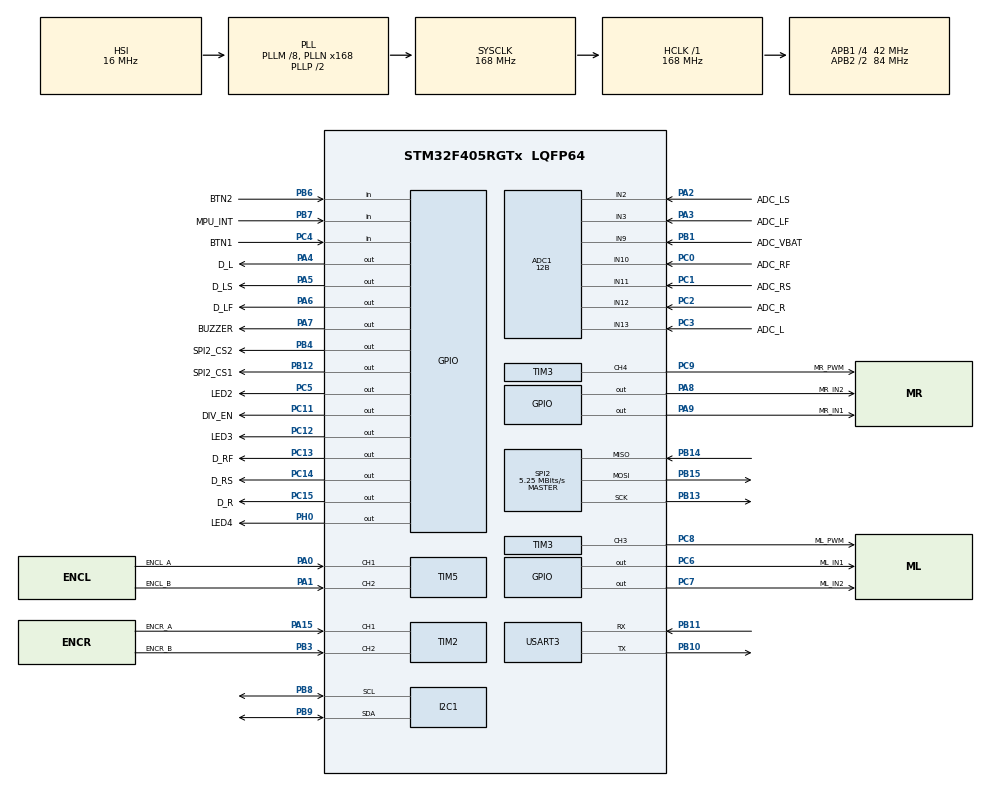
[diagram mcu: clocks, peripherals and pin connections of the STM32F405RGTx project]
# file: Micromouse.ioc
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ADC1.Channel-15\#ChannelRegularConversion=ADC_CHANNEL_12
ADC1.Channel-16\#ChannelRegularConversion=ADC_CHANNEL_2
ADC1.Channel-17\#ChannelRegularConversion=ADC_CHANNEL_11
ADC1.Channel-18\#ChannelRegularConversion=ADC_CHANNEL_3
ADC1.Channel-19\#ChannelRegularConversion=ADC_CHANNEL_10
ADC1.Channel-8\#ChannelRegularConversion=ADC_CHANNEL_13
ADC1.ClockPrescaler=ADC_CLOCK_SYNC_PCLK_DIV4
ADC1.ContinuousConvMode=DISABLE
ADC1.DMAContinuousRequests=ENABLE
ADC1.DataAlign=ADC_DATAALIGN_RIGHT
ADC1.DiscontinuousConvMode=DISABLE
ADC1.EOCSelection=ADC_EOC_SEQ_CONV
ADC1.EnableAnalogWatchDog=false
ADC1.ExternalTrigConv=ADC_SOFTWARE_START
ADC1.ExternalTrigConvEdge=ADC_EXTERNALTRIGCONVEDGE_NONE
ADC1.InjNumberOfConversion=0
ADC1.NbrOfConversion=6
ADC1.NbrOfConversionFlag=1
ADC1.Rank-15\#ChannelRegularConversion=2
ADC1.Rank-16\#ChannelRegularConversion=3
ADC1.Rank-17\#ChannelRegularConversion=4
ADC1.Rank-18\#ChannelRegularConversion=5
ADC1.Rank-19\#ChannelRegularConversion=6
ADC1.Rank-8\#ChannelRegularConversion=1
ADC1.Resolution=ADC_RESOLUTION_12B
ADC1.SamplingTime-15\#ChannelRegularConversion=ADC_SAMPLETIME_84CYCLES
ADC1.SamplingTime-16\#ChannelRegularConversion=ADC_SAMPLETIME_84CYCLES
ADC1.SamplingTime-17\#ChannelRegularConversion=ADC_SAMPLETIME_84CYCLES
ADC1.SamplingTime-18\#ChannelRegularConversion=ADC_SAMPLETIME_84CYCLES
ADC1.SamplingTime-19\#ChannelRegularConversion=ADC_SAMPLETIME_84CYCLES
ADC1.SamplingTime-8\#ChannelRegularConversion=ADC_SAMPLETIME_84CYCLES
ADC1.ScanConvMode=ENABLE
ADC1.master=1
Dma.ADC1.3.Direction=DMA_PERIPH_TO_MEMORY
Dma.ADC1.3.FIFOMode=DMA_FIFOMODE_DISABLE
Dma.ADC1.3.Instance=DMA2_Stream0
Dma.ADC1.3.MemDataAlignment=DMA_MDATAALIGN_WORD
Dma.ADC1.3.MemInc=DMA_MINC_ENABLE
Dma.ADC1.3.Mode=DMA_NORMAL
Dma.ADC1.3.PeriphDataAlignment=DMA_PDATAALIGN_WORD
Dma.ADC1.3.PeriphInc=DMA_PINC_DISABLE
Dma.ADC1.3.Priority=DMA_PRIORITY_HIGH
Dma.I2C1_RX.0.Direction=DMA_PERIPH_TO_MEMORY
Dma.I2C1_RX.0.FIFOMode=DMA_FIFOMODE_DISABLE
Dma.I2C1_RX.0.Instance=DMA1_Stream0
Dma.I2C1_RX.0.MemDataAlignment=DMA_MDATAALIGN_BYTE
Dma.I2C1_RX.0.MemInc=DMA_MINC_ENABLE
Dma.I2C1_RX.0.Mode=DMA_NORMAL
Dma.I2C1_RX.0.PeriphDataAlignment=DMA_PDATAALIGN_BYTE
Dma.I2C1_RX.0.PeriphInc=DMA_PINC_DISABLE
Dma.I2C1_RX.0.Priority=DMA_PRIORITY_HIGH
Dma.Request0=I2C1_RX
Dma.Request1=USART3_TX
Dma.Request2=USART3_RX
Dma.Request3=ADC1
Dma.USART3_RX.2.Direction=DMA_PERIPH_TO_MEMORY
Dma.USART3_RX.2.FIFOMode=DMA_FIFOMODE_DISABLE
Dma.USART3_RX.2.Instance=DMA1_Stream1
Dma.USART3_RX.2.MemDataAlignment=DMA_MDATAALIGN_BYTE
Dma.USART3_RX.2.MemInc=DMA_MINC_ENABLE
Dma.USART3_RX.2.Mode=DMA_NORMAL
Dma.USART3_RX.2.PeriphDataAlignment=DMA_PDATAALIGN_BYTE
Dma.USART3_RX.2.PeriphInc=DMA_PINC_DISABLE
Dma.USART3_RX.2.Priority=DMA_PRIORITY_LOW
Dma.USART3_TX.1.Direction=DMA_MEMORY_TO_PERIPH
Dma.USART3_TX.1.FIFOMode=DMA_FIFOMODE_DISABLE
Dma.USART3_TX.1.Instance=DMA1_Stream3
Dma.USART3_TX.1.MemDataAlignment=DMA_MDATAALIGN_BYTE
Dma.USART3_TX.1.MemInc=DMA_MINC_ENABLE
Dma.USART3_TX.1.Mode=DMA_NORMAL
Dma.USART3_TX.1.PeriphDataAlignment=DMA_PDATAALIGN_BYTE
Dma.USART3_TX.1.PeriphInc=DMA_PINC_DISABLE
Dma.USART3_TX.1.Priority=DMA_PRIORITY_LOW
Mcu.Family=STM32F4
Mcu.Name=STM32F405RGTx
Mcu.Package=LQFP64
NVIC.DMA1_Stream0_IRQn=true\:0\:0\:false\:false\:true\:false
NVIC.DMA1_Stream1_IRQn=true\:0\:0\:false\:false\:true\:false
NVIC.DMA1_Stream3_IRQn=true\:0\:0\:false\:false\:true\:false
NVIC.DMA2_Stream0_IRQn=true\:0\:0\:false\:false\:true\:true
NVIC.I2C1_EV_IRQn=true\:0\:0\:false\:false\:true\:true
NVIC.PriorityGroup=NVIC_PRIORITYGROUP_4
NVIC.TIM1_UP_TIM10_IRQn=true\:0\:0\:false\:false\:true\:true
NVIC.TIM7_IRQn=true\:0\:0\:false\:false\:true\:true
PA0-WKUP.GPIO_Label=ENCL_A
PA0-WKUP.Signal=S_TIM5_CH1
PA1.GPIO_Label=ENCL_B
PA1.Signal=S_TIM5_CH2
PA13.Mode=Serial_Wire
PA13.Signal=SYS_JTMS-SWDIO
PA14.Mode=Serial_Wire
PA14.Signal=SYS_JTCK-SWCLK
PA15.GPIO_Label=ENCR_A
PA15.Signal=S_TIM2_CH1_ETR
PA2.GPIO_Label=ADC_LS
PA2.Signal=ADCx_IN2
PA3.GPIO_Label=ADC_LF
PA3.Signal=ADCx_IN3
PA4.GPIO_Label=D_L
PA4.GPIO_PuPd=GPIO_PULLDOWN
PA4.Signal=GPIO_Output
PA5.GPIO_Label=D_LS
PA5.GPIO_PuPd=GPIO_PULLDOWN
PA5.Signal=GPIO_Output
PA6.GPIO_Label=D_LF
PA6.GPIO_PuPd=GPIO_PULLDOWN
PA6.Signal=GPIO_Output
PA7.GPIO_Label=BUZZER
PA7.GPIO_PuPd=GPIO_PULLDOWN
PA7.Signal=GPIO_Output
PA8.GPIO_Label=MR_IN2
PA8.Signal=GPIO_Output
PA9.GPIO_Label=MR_IN1
PA9.Signal=GPIO_Output
PB1.GPIO_Label=ADC_VBAT
PB1.Signal=ADCx_IN9
PB10.Mode=Asynchronous
PB10.Signal=USART3_TX
PB11.Mode=Asynchronous
PB11.Signal=USART3_RX
PB12.GPIO_Label=SPI2_CS1
PB12.GPIO_PuPd=GPIO_PULLUP
PB12.PinState=GPIO_PIN_SET
PB12.Signal=GPIO_Output
PB13.Mode=Full_Duplex_Master
PB13.Signal=SPI2_SCK
PB14.Mode=Full_Duplex_Master
PB14.Signal=SPI2_MISO
PB15.Mode=Full_Duplex_Master
PB15.Signal=SPI2_MOSI
PB3.GPIO_Label=ENCR_B
PB3.Signal=S_TIM2_CH2
PB4.GPIO_Label=SPI2_CS2
PB4.GPIO_PuPd=GPIO_PULLUP
PB4.PinState=GPIO_PIN_SET
PB4.Signal=GPIO_Output
PB6.GPIO_Label=BTN2
PB6.Signal=GPIO_Input
PB7.GPIO_Label=MPU_INT
PB7.Signal=GPIO_Input
PB8.Mode=I2C
PB8.Signal=I2C1_SCL
PB9.Mode=I2C
PB9.Signal=I2C1_SDA
PC0.GPIO_Label=ADC_RF
PC0.Signal=ADCx_IN10
PC1.GPIO_Label=ADC_RS
PC1.Signal=ADCx_IN11
PC11.GPIO_Label=DIV_EN
PC11.GPIO_PuPd=GPIO_PULLDOWN
PC11.Signal=GPIO_Output
PC12.GPIO_Label=LED3
PC12.PinState=GPIO_PIN_SET
PC12.Signal=GPIO_Output
PC13-ANTI_TAMP.GPIO_Label=D_RF
PC13-ANTI_TAMP.GPIO_PuPd=GPIO_PULLDOWN
PC13-ANTI_TAMP.Signal=GPIO_Output
PC14-OSC32_IN.GPIO_Label=D_RS
PC14-OSC32_IN.GPIO_PuPd=GPIO_PULLDOWN
PC14-OSC32_IN.Signal=GPIO_Output
PC15-OSC32_OUT.GPIO_Label=D_R
PC15-OSC32_OUT.GPIO_PuPd=GPIO_PULLDOWN
PC15-OSC32_OUT.Signal=GPIO_Output
PC2.GPIO_Label=ADC_R
PC2.Signal=ADCx_IN12
PC3.GPIO_Label=ADC_L
PC3.Signal=ADCx_IN13
PC4.GPIO_Label=BTN1
PC4.Signal=GPIO_Input
PC5.GPIO_Label=LED2
PC5.PinState=GPIO_PIN_SET
PC5.Signal=GPIO_Output
PC6.GPIO_Label=ML_IN1
PC6.Signal=GPIO_Output
PC7.GPIO_Label=ML_IN2
PC7.Signal=GPIO_Output
PC8.GPIO_Label=ML_PWM
PC8.Signal=S_TIM3_CH3
PC9.GPIO_Label=MR_PWM
PC9.Signal=S_TIM3_CH4
PH0-OSC_IN.GPIO_Label=LED4
PH0-OSC_IN.PinState=GPIO_PIN_SET
PH0-OSC_IN.Signal=GPIO_Output
ProjectManager.HeapSize=0x200
ProjectManager.StackSize=0x400
ProjectManager.TargetToolchain=SW4STM32
RCC.48MHZClocksFreq_Value=84000000
RCC.AHBFreq_Value=168000000
RCC.APB1CLKDivider=RCC_HCLK_DIV4
RCC.APB1Freq_Value=42000000
RCC.APB1TimFreq_Value=84000000
RCC.APB2CLKDivider=RCC_HCLK_DIV2
RCC.APB2Freq_Value=84000000
RCC.APB2TimFreq_Value=168000000
RCC.CortexFreq_Value=168000000
RCC.HCLKFreq_Value=168000000
RCC.HSE_VALUE=8000000
RCC.HSI_VALUE=16000000
RCC.LSE_VALUE=32768
RCC.PLLM=8
RCC.PLLN=168
RCC.SYSCLKFreq_VALUE=168000000
RCC.SYSCLKSource=RCC_SYSCLKSOURCE_PLLCLK
RCC.VCOOutputFreq_Value=336000000
SH.ADCx_IN10.0=ADC1_IN10,IN10
SH.ADCx_IN11.0=ADC1_IN11,IN11
SH.ADCx_IN12.0=ADC1_IN12,IN12
SH.ADCx_IN13.0=ADC1_IN13,IN13
SH.ADCx_IN2.0=ADC1_IN2,IN2
SH.ADCx_IN3.0=ADC1_IN3,IN3
SH.ADCx_IN9.0=ADC1_IN9,IN9
SH.S_TIM2_CH1_ETR.0=TIM2_CH1,Encoder_Interface
SH.S_TIM2_CH2.0=TIM2_CH2,Encoder_Interface
SH.S_TIM3_CH3.0=TIM3_CH3,PWM Generation3 CH3
SH.S_TIM3_CH4.0=TIM3_CH4,PWM Generation4 CH4
SH.S_TIM5_CH1.0=TIM5_CH1,Encoder_Interface
SH.S_TIM5_CH2.0=TIM5_CH2,Encoder_Interface
SPI2.BaudRatePrescaler=SPI_BAUDRATEPRESCALER_8
SPI2.CLKPhase=SPI_PHASE_2EDGE
SPI2.CalculateBaudRate=5.25 MBits/s
SPI2.DataSize=SPI_DATASIZE_16BIT
SPI2.Direction=SPI_DIRECTION_2LINES
SPI2.Mode=SPI_MODE_MASTER
SPI2.VirtualType=VM_MASTER
TIM10.Period=1000
TIM10.Prescaler=65535
TIM3.Channel-PWM\ Generation3\ CH3=TIM_CHANNEL_3
TIM3.Channel-PWM\ Generation4\ CH4=TIM_CHANNEL_4
TIM7.Period=39
TIM7.Prescaler=84
USART3.VirtualMode=VM_ASYNC
VP_ADC1_TempSens_Input.Mode=IN-TempSens
VP_ADC1_Vref_Input.Mode=IN-Vrefint
VP_TIM10_VS_ClockSourceINT.Mode=Enable_Timer
VP_TIM6_VS_ClockSourceINT.Mode=Enable_Timer
VP_TIM7_VS_ClockSourceINT.Mode=Enable_Timer
board=Micromouse

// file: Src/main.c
/**
  ******************************************************************************
  * File Name          : main.c
  * Description        : Main program body
  ******************************************************************************
  ** This notice applies to any and all portions of this file
  * that are not between comment pairs USER CODE BEGIN and
  * USER CODE END. Other portions of this file, whether
  * inserted by the user or by software development tools
  * are owned by their respective copyright owners.
  *
  * COPYRIGHT(c) 2017 STMicroelectronics
  *
  * Redistribution and use in source and binary forms, with or without modification,
  * are permitted provided that the following conditions are met:
  *   1. Redistributions of source code must retain the above copyright notice,
  *      this list of conditions and the following disclaimer.
  *   2. Redistributions in binary form must reproduce the above copyright notice,
  *      this list of conditions and the following disclaimer in the documentation
  *      and/or other materials provided with the distribution.
  *   3. Neither the name of STMicroelectronics nor the names of its contributors
  *      may be used to endorse or promote products derived from this software
  *      without specific prior written permission.
  *
  * THIS SOFTWARE IS PROVIDED BY THE COPYRIGHT HOLDERS AND CONTRIBUTORS "AS IS"
  * AND ANY EXPRESS OR IMPLIED WARRANTIES, INCLUDING, BUT NOT LIMITED TO, THE
  * IMPLIED WARRANTIES OF MERCHANTABILITY AND FITNESS FOR A PARTICULAR PURPOSE ARE
  * DISCLAIMED. IN NO EVENT SHALL THE COPYRIGHT HOLDER OR CONTRIBUTORS BE LIABLE
  * FOR ANY DIRECT, INDIRECT, INCIDENTAL, SPECIAL, EXEMPLARY, OR CONSEQUENTIAL
  * DAMAGES (INCLUDING, BUT NOT LIMITED TO, PROCUREMENT OF SUBSTITUTE GOODS OR
  * SERVICES; LOSS OF USE, DATA, OR PROFITS; OR BUSINESS INTERRUPTION) HOWEVER
  * CAUSED AND ON ANY THEORY OF LIABILITY, WHETHER IN CONTRACT, STRICT LIABILITY,
  * OR TORT (INCLUDING NEGLIGENCE OR OTHERWISE) ARISING IN ANY WAY OUT OF THE USE
  * OF THIS SOFTWARE, EVEN IF ADVISED OF THE POSSIBILITY OF SUCH DAMAGE.
  *
  ******************************************************************************
  */
#include "main.h"
#include "stm32f4xx_hal.h"
#include "adc.h"
#include "dma.h"
#include "i2c.h"
#include "spi.h"
#include "tim.h"
#include "usart.h"
#include "gpio.h"

/* USER CODE BEGIN Includes */
//#include "port/as5147p.h"
//#include "port/mpu6050.h"
//#include "utils/logger.h"
//#include "Utils/fusion.h"
#include "mymain.h"

/* USER CODE END Includes */

/* USER CODE BEGIN PV */
/* Private variables ---------------------------------------------------------*/

/* USER CODE END PV */

void SystemClock_Config(void);

/* USER CODE BEGIN PFP */
/* Private function prototypes -----------------------------------------------*/

/* USER CODE END PFP */

/* USER CODE BEGIN 0 */
int16_t test[6];
/* USER CODE END 0 */

int main(void)
{

  /* MCU Configuration----------------------------------------------------------*/

  /* Reset of all peripherals, Initializes the Flash interface and the Systick. */
  HAL_Init();

  /* Configure the system clock */
  SystemClock_Config();

  /* Initialize all configured peripherals */
  MX_GPIO_Init();
  MX_DMA_Init();
  MX_ADC1_Init();
  MX_TIM6_Init();
  MX_TIM2_Init();
  MX_TIM5_Init();
  MX_I2C1_Init();
  MX_SPI2_Init();
  MX_TIM3_Init();
  MX_USART3_UART_Init();
  MX_TIM7_Init();
  MX_TIM10_Init();

  /* USER CODE BEGIN 2 */
  //HAL_TIM_Base_Start_IT(&htim7); // led timer
	//logger_init();
//	if(mpu_self_test()){
//		while(1);
//	}
//	mpu_init();
//	mpu_calibrate();
//  if(mpu_selftest())
//	  while(1);
  /* USER CODE BEGIN 2 */

	initModules();
  /* USER CODE END 2 */

  /* Infinite loop */
  while (1)
  {

  /* USER CODE BEGIN 3 */
	everyCycleFun();
  	HAL_Delay(1);
//  	everyCycleFun();

  }
  /* USER CODE END 3 */

}

/** System Clock Configuration
*/
void SystemClock_Config(void)
{

  RCC_OscInitTypeDef RCC_OscInitStruct;
  RCC_ClkInitTypeDef RCC_ClkInitStruct;

    /**Configure the main internal regulator output voltage
    */
  __HAL_RCC_PWR_CLK_ENABLE();

  __HAL_PWR_VOLTAGESCALING_CONFIG(PWR_REGULATOR_VOLTAGE_SCALE1);

    /**Initializes the CPU, AHB and APB busses clocks
    */
  RCC_OscInitStruct.OscillatorType = RCC_OSCILLATORTYPE_HSI;
  RCC_OscInitStruct.HSIState = RCC_HSI_ON;
  RCC_OscInitStruct.HSICalibrationValue = 16;
  RCC_OscInitStruct.PLL.PLLState = RCC_PLL_ON;
  RCC_OscInitStruct.PLL.PLLSource = RCC_PLLSOURCE_HSI;
  RCC_OscInitStruct.PLL.PLLM = 8;
  RCC_OscInitStruct.PLL.PLLN = 168;
  RCC_OscInitStruct.PLL.PLLP = RCC_PLLP_DIV2;
  RCC_OscInitStruct.PLL.PLLQ = 4;
  if (HAL_RCC_OscConfig(&RCC_OscInitStruct) != HAL_OK)
  {
    _Error_Handler(__FILE__, __LINE__);
  }

    /**Initializes the CPU, AHB and APB busses clocks
    */
  RCC_ClkInitStruct.ClockType = RCC_CLOCKTYPE_HCLK|RCC_CLOCKTYPE_SYSCLK
                              |RCC_CLOCKTYPE_PCLK1|RCC_CLOCKTYPE_PCLK2;
  RCC_ClkInitStruct.SYSCLKSource = RCC_SYSCLKSOURCE_PLLCLK;
  RCC_ClkInitStruct.AHBCLKDivider = RCC_SYSCLK_DIV1;
  RCC_ClkInitStruct.APB1CLKDivider = RCC_HCLK_DIV4;
  RCC_ClkInitStruct.APB2CLKDivider = RCC_HCLK_DIV2;

  if (HAL_RCC_ClockConfig(&RCC_ClkInitStruct, FLASH_LATENCY_5) != HAL_OK)
  {
    _Error_Handler(__FILE__, __LINE__);
  }

    /**Configure the Systick interrupt time
    */
  HAL_SYSTICK_Config(HAL_RCC_GetHCLKFreq()/1000);

    /**Configure the Systick
    */
  HAL_SYSTICK_CLKSourceConfig(SYSTICK_CLKSOURCE_HCLK);

  /* SysTick_IRQn interrupt configuration */
  HAL_NVIC_SetPriority(SysTick_IRQn, 0, 0);
}

void _Error_Handler(char * file, int line)
{
  while(1)
  {
  }
}

/************************ (C) COPYRIGHT STMicroelectronics *****END OF FILE****/
